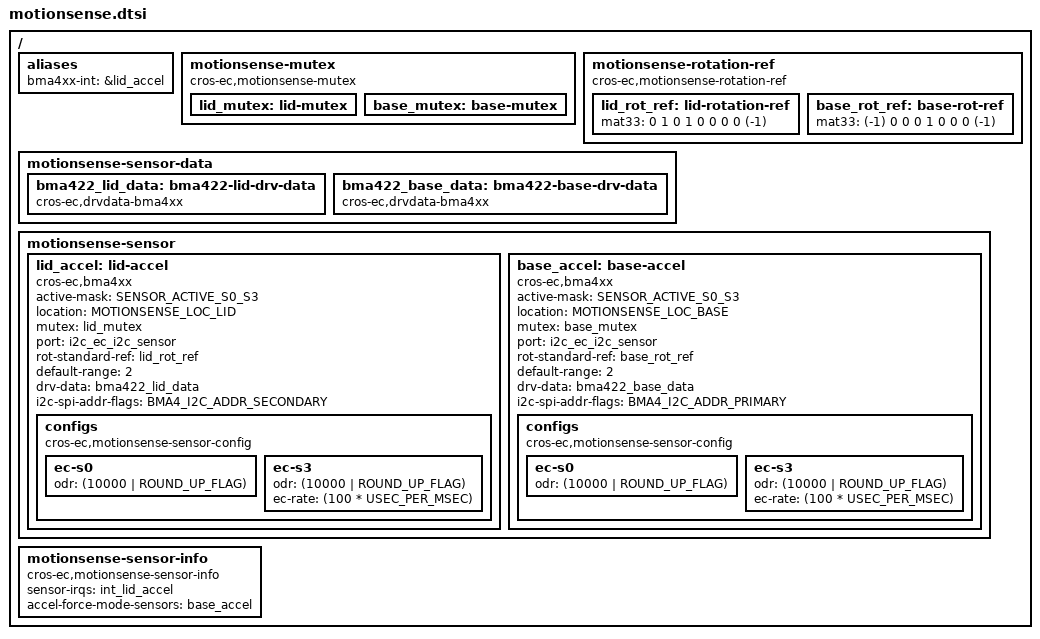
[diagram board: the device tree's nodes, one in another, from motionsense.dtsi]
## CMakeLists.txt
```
# Copyright 2024 The ChromiumOS Authors
# Use of this source code is governed by a BSD-style license that can be
# found in the LICENSE file.

zephyr_library_sources("src/board_nb_mode.c")
```

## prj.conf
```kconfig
# Copyright 2024 The ChromiumOS Authors
# Use of this source code is governed by a BSD-style license that can be
# found in the LICENSE file.

CONFIG_NISSA_SUB_BOARD=n

# Fix compile issue
CONFIG_CROS_EC_RAM_BASE=0xff216900
CONFIG_CROS_EC_RAM_SIZE=0x00015000
CONFIG_CROS_EC_DATA_RAM_SIZE=0x00010000
CONFIG_CROS_EC_PROGRAM_MEMORY_BASE=0x10090000
CONFIG_CROS_EC_RO_MEM_OFF=0x0
CONFIG_CROS_EC_RO_SIZE=0xb000
CONFIG_CROS_EC_RW_MEM_OFF=0xb000
CONFIG_CROS_EC_RW_SIZE=0x75000

CONFIG_PLATFORM_EC=y
CONFIG_CROS_EC=y
CONFIG_SHIMMED_TASKS=y
CONFIG_SYSCON=y

# Disable default features
CONFIG_NAMED_ADC_CHANNELS=n
CONFIG_PWM=n
CONFIG_PLATFORM_EC_BACKLIGHT_LID=n
CONFIG_PLATFORM_EC_KEYBOARD=n
CONFIG_PLATFORM_EC_POWER_BUTTON=n
CONFIG_PLATFORM_EC_SWITCH=n
CONFIG_PLATFORM_EC_VBOOT_EFS2=n
CONFIG_PLATFORM_EC_VBOOT_HASH=n
CONFIG_PLATFORM_EC_PANIC=y
CONFIG_PLATFORM_EC_CBI_GPIO=n

# Log
CONFIG_LOG=y
CONFIG_LOG_MODE_MINIMAL=y

# Host Interface and  MKBP event
CONFIG_PLATFORM_EC_HOST_INTERFACE_HECI=y
CONFIG_PLATFORM_EC_MKBP_EVENT=y
CONFIG_PLATFORM_EC_MKBP_USE_HECI=y

# ISH BSP config
CONFIG_IPM=y
CONFIG_HECI=y
CONFIG_HOST_SERVICE=y
CONFIG_HECI_INTF_IPM=y
CONFIG_REBOOT=y
CONFIG_SPI=n
CONFIG_GPIO=y

# Common sensor configs
CONFIG_PLATFORM_EC_ACCEL_FIFO=y
CONFIG_PLATFORM_EC_DYNAMIC_MOTION_SENSOR_COUNT=y
CONFIG_PLATFORM_EC_LID_ANGLE=y
CONFIG_PLATFORM_EC_LID_ANGLE_UPDATE=y
CONFIG_PLATFORM_EC_SENSOR_TIGHT_TIMESTAMPS=y
CONFIG_PLATFORM_EC_GMR_TABLET_MODE=n
CONFIG_PLATFORM_EC_TABLET_MODE=y
CONFIG_PLATFORM_EC_TABLET_MODE_SWITCH=n
CONFIG_PLATFORM_EC_LID_SWITCH=n
CONFIG_PLATFORM_EC_SENSOR_EC_RATE_FORCE_MODE=y

# Sensor console commands
CONFIG_PLATFORM_EC_CONSOLE_CMD_ACCELS=y
CONFIG_PLATFORM_EC_CONSOLE_CMD_ACCEL_INFO=y


#ISH PM
CONFIG_PM=y
CONFIG_PM_DEVICE=y
CONFIG_PM_DEVICE_RUNTIME=n
CONFIG_GDT_DYNAMIC=y
CONFIG_GDT_RESERVED_NUM_ENTRIES=3
CONFIG_PLATFORM_EC_CONSOLE_CMD_SLEEPMASK=n

# Other
CONFIG_SHELL_PROMPT_UART="ish:~$ "
CONFIG_SHELL_BACKEND_SERIAL_INTERRUPT_DRIVEN=n
CONFIG_SHELL_BACKEND_SERIAL_RX_POLL_PERIOD=60000

# Sensor Console Commands
CONFIG_PLATFORM_EC_CONSOLE_CMD_I2C_SPEED=y

# Notify EC for clamshell/tablet mode change
CONFIG_EVENTS=y
CONFIG_DSP_COMMS_LOG_LEVEL_DBG=y
CONFIG_PLATFORM_EC_DSP_REMOTE_CBI=y
CONFIG_PLATFORM_EC_DSP_REMOTE_LID_SWITCH=y
CONFIG_PLATFORM_EC_DSP_REMOTE_TABLET_SWITCH=y
```

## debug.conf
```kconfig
# Copyright 2025 The ChromiumOS Authors
# Use of this source code is governed by a BSD-style license that can be
# found in the LICENSE file.

# Update the logging to be more verbose
CONFIG_LOG_MODE_MINIMAL=n
CONFIG_LOG_MODE_DEFERRED=y
CONFIG_SHELL_LOG_FORMAT_TIMESTAMP=y

# Disable power management
CONFIG_PM=n

# Reduce the polling rate for UART so it's responsive
CONFIG_SHELL_BACKEND_SERIAL_RX_POLL_PERIOD=100
```

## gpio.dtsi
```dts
/* Copyright 2024 The ChromiumOS Authors
 * Use of this source code is governed by a BSD-style license that can be
 * found in the LICENSE file.
 */
#include <dt-bindings/gpio_defines.h>

/ {

	named-gpios {
		compatible = "named-gpios";

		gpio_acc_int_l: acc_int_l {
			gpios = <&gpio0 0 GPIO_INPUT>;
		};

		gpio_imu_int_l: imu_int_l {
			gpios = <&gpio0 1 GPIO_INPUT>;
		};

		gpio_lid_open: lid_open {
			gpios = <&gpio0 6 GPIO_INPUT>;
			enum-name = "GPIO_LID_OPEN";
		};

		gpio_tablet_mode_int_l: lid_sw2_soc {
			gpios = <&gpio0 7 GPIO_INPUT>;
			enum-name = "GPIO_TABLET_MODE_L";
		};

		ec_entering_rw {
			enum-name = "GPIO_ENTERING_RW";
		};
	};
};
```

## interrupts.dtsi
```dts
/* Copyright 2024 The ChromiumOS Authors
 * Use of this source code is governed by a BSD-style license that can be
 * found in the LICENSE file.
 */

/ {
	gpio_interrupts: gpio-interrupts {
		compatible = "cros-ec,gpio-interrupts";
	};
};

#include "../orisa/interrupts_motionsense.dtsi"
```

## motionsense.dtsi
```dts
/* Copyright 2021 The ChromiumOS Authors
 * Use of this source code is governed by a BSD-style license that can be
 * found in the LICENSE file.
 */

#include <dt-bindings/motionsense/utils.h>


/ {
	aliases {
		/*
		 * Interrupt bindings for sensor devices.
		 */
		 bma4xx-int = &lid_accel;
	};

	/*
	 * Declare mutexes used by sensor drivers.
	 * A mutex node is used to create an instance of mutex_t.
	 * A mutex node is referenced by a sensor node if the
	 * corresponding sensor driver needs to use the
	 * instance of the mutex.
	 */
	motionsense-mutex {
		compatible = "cros-ec,motionsense-mutex";
		lid_mutex: lid-mutex {
		};

		base_mutex: base-mutex {
		};
	};

	/* Rotation matrix used by drivers. */
	motionsense-rotation-ref {
		compatible = "cros-ec,motionsense-rotation-ref";
		lid_rot_ref: lid-rotation-ref {
			mat33 = <0 1 0
				 1 0 0
				 0 0 (-1)>;
		};

		base_rot_ref: base-rot-ref {
			mat33 = <(-1) 0 0
				 0 1 0
				 0 0 (-1)>;
		};
	};

	/*
	 * Driver specific data. A driver-specific data can be shared with
	 * different motion sensors while they are using the same driver.
	 *
	 * If a node's compatible starts with "cros-ec,accelgyro-", it is for
	 * a common structure defined in accelgyro.h.
	 * e.g) compatible = "cros-ec,accelgyro-als-drv-data" is for
	 * "struct als_drv_data_t" in accelgyro.h
	 */
	motionsense-sensor-data {
		bma422_lid_data: bma422-lid-drv-data {
			compatible = "cros-ec,drvdata-bma4xx";
			status = "okay";
		};
		bma422_base_data: bma422-base-drv-data {
			compatible = "cros-ec,drvdata-bma4xx";
			status = "okay";
		};
	};

	/*
	 * List of motion sensors that creates motion_sensors array.
	 * The nodelabel "lid_accel" and "base_accel" are used to indicate
	 * motion sensor IDs for lid angle calculation.
	 * TODO(b/238139272): The first entries of the array must be
	 * accelerometers,then gyroscope. Fix this dependency in the DTS
	 * processing which makes the devicetree entries independent.
	 */
	motionsense-sensor {
		lid_accel: lid-accel {
			compatible = "cros-ec,bma4xx";
			status = "okay";

			active-mask = "SENSOR_ACTIVE_S0_S3";
			location = "MOTIONSENSE_LOC_LID";
			mutex = <&lid_mutex>;
			port = <&i2c_ec_i2c_sensor>;
			rot-standard-ref = <&lid_rot_ref>;
			default-range = <2>;
			drv-data = <&bma422_lid_data>;
			i2c-spi-addr-flags = "BMA4_I2C_ADDR_SECONDARY";
			configs {
				compatible =
					"cros-ec,motionsense-sensor-config";
				ec-s0 {
					odr = <(10000 | ROUND_UP_FLAG)>;
				};
				ec-s3 {
					odr = <(10000 | ROUND_UP_FLAG)>;
					ec-rate = <(100 * USEC_PER_MSEC)>;
				};
			};
		};

		base_accel: base-accel {
			compatible = "cros-ec,bma4xx";
			status = "okay";

			active-mask = "SENSOR_ACTIVE_S0_S3";
			location = "MOTIONSENSE_LOC_BASE";
			mutex = <&base_mutex>;
			port = <&i2c_ec_i2c_sensor>;
			rot-standard-ref = <&base_rot_ref>;
			default-range = <2>;
			drv-data = <&bma422_base_data>;
			i2c-spi-addr-flags = "BMA4_I2C_ADDR_PRIMARY";
			configs {
				compatible =
					"cros-ec,motionsense-sensor-config";
				ec-s0 {
					odr = <(10000 | ROUND_UP_FLAG)>;
				};
				ec-s3 {
					odr = <(10000 | ROUND_UP_FLAG)>;
					ec-rate = <(100 * USEC_PER_MSEC)>;
				};
			};
		};
	};

	motionsense-sensor-info {
		compatible = "cros-ec,motionsense-sensor-info";

		/*
		 * list of GPIO interrupts that have to
		 * be enabled at initial stage
		 */
		sensor-irqs = <&int_lid_accel>;
		/* list of sensors in force mode */
		accel-force-mode-sensors = <&base_accel>;
	};
};
```

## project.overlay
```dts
/* Copyright 2024 The ChromiumOS Authors
 * Use of this source code is governed by a BSD-style license that can be
 * found in the LICENSE file.
 */

/* brox-ish project DTSI includes */
#include "gpio.dtsi"
#include "i2c.dtsi"
#include "interrupts.dtsi"
#include "ish.dtsi"
#include "../orisa/motionsense.dtsi"
```

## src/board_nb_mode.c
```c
/* Copyright 2024 The ChromiumOS Authors
 * Use of this source code is governed by a BSD-style license that can be
 * found in the LICENSE file.
 */

#include "hooks.h"
#include "tablet_mode.h"

static void board_nb_mode_change(void)
{
	/*
	 * gpio_soc_ec_ish_nb_mode_l is an active low pin; default level is
	 * low. This pin is an output from SOC (ISH) to EC.
	 *
	 * In this config, ISH runs motion sense task; while EC doesn't.
	 * When ISH motion sense task detects notebook(clamshell)/tablet mode
	 * changes, ISH will notify EC about the change by updating this pin.
	 *
	 * Set this gpio to low if changing to notebook(clamshell) mode;
	 * Set this gpio to high if changing to tablet mode.
	 */
	gpio_pin_set_dt(GPIO_DT_FROM_NODELABEL(gpio_soc_ec_ish_nb_mode_l),
			tablet_get_mode());
}
DECLARE_HOOK(HOOK_TABLET_MODE_CHANGE, board_nb_mode_change, HOOK_PRIO_DEFAULT);
```
